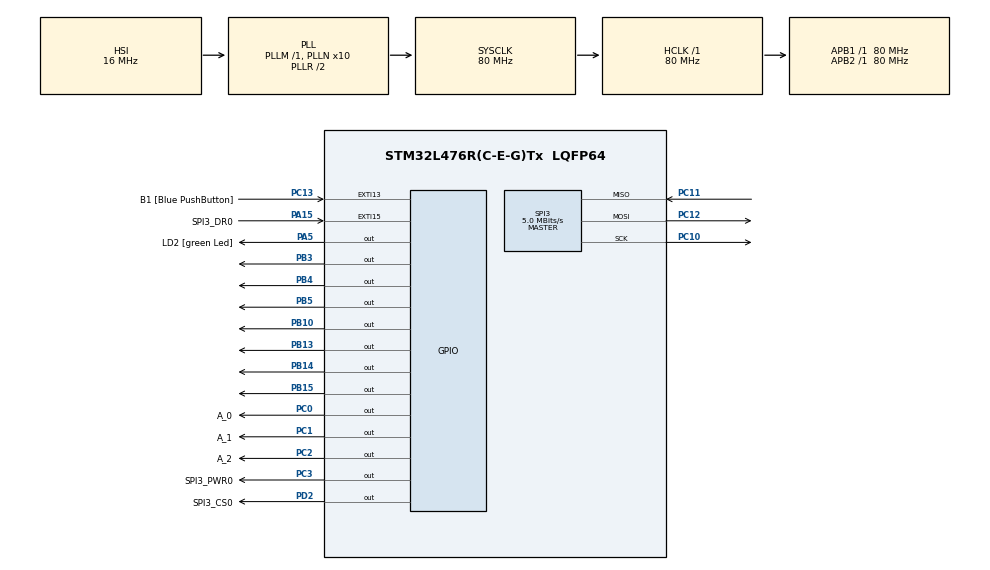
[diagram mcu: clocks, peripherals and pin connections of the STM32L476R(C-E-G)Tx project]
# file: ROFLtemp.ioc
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Mcu.Family=STM32L4
Mcu.Name=STM32L476R(C-E-G)Tx
Mcu.Package=LQFP64
NVIC.EXTI15_10_IRQn=true\:0\:0\:false\:false\:true
NVIC.PriorityGroup=NVIC_PRIORITYGROUP_4
NVIC.SPI3_IRQn=true\:0\:0\:false\:false\:true
NVIC.TIM6_DAC_IRQn=true\:0\:0\:false\:false\:true
PA13.GPIO_Label=TMS
PA13.Signal=SYS_JTMS-SWDIO
PA14.GPIO_Label=TCK
PA14.Signal=SYS_JTCK-SWCLK
PA15.GPIO_Label=SPI3_DR0
PA15.Signal=GPXTI15
PA2.GPIO_Label=USART_TX
PA2.GPIO_Mode=GPIO_MODE_AF_PP
PA2.GPIO_PuPd=GPIO_NOPULL
PA2.GPIO_Speed=GPIO_SPEED_FREQ_VERY_HIGH
PA2.Signal=USART2_TX
PA3.GPIO_Label=USART_RX
PA3.GPIO_Mode=GPIO_MODE_AF_PP
PA3.GPIO_PuPd=GPIO_NOPULL
PA3.GPIO_Speed=GPIO_SPEED_FREQ_VERY_HIGH
PA3.Signal=USART2_RX
PA5.GPIO_Label=LD2 [green Led]
PA5.GPIO_ModeDefaultOutputPP=GPIO_MODE_OUTPUT_PP
PA5.GPIO_PuPd=GPIO_NOPULL
PA5.GPIO_Speed=GPIO_SPEED_FREQ_LOW
PA5.Signal=GPIO_Output
PB10.GPIO_ModeDefaultOutputPP=GPIO_MODE_OUTPUT_PP
PB10.GPIO_Speed=GPIO_SPEED_FREQ_MEDIUM
PB10.PinState=GPIO_PIN_SET
PB10.Signal=GPIO_Output
PB13.GPIO_ModeDefaultOutputPP=GPIO_MODE_OUTPUT_PP
PB13.GPIO_Speed=GPIO_SPEED_FREQ_MEDIUM
PB13.PinState=GPIO_PIN_SET
PB13.Signal=GPIO_Output
PB14.GPIO_ModeDefaultOutputPP=GPIO_MODE_OUTPUT_PP
PB14.GPIO_Speed=GPIO_SPEED_FREQ_MEDIUM
PB14.PinState=GPIO_PIN_SET
PB14.Signal=GPIO_Output
PB15.GPIO_ModeDefaultOutputPP=GPIO_MODE_OUTPUT_PP
PB15.GPIO_Speed=GPIO_SPEED_FREQ_MEDIUM
PB15.PinState=GPIO_PIN_SET
PB15.Signal=GPIO_Output
PB3.GPIO_ModeDefaultOutputPP=GPIO_MODE_OUTPUT_PP
PB3.GPIO_Speed=GPIO_SPEED_FREQ_MEDIUM
PB3.PinState=GPIO_PIN_SET
PB3.Signal=GPIO_Output
PB4.GPIO_ModeDefaultOutputPP=GPIO_MODE_OUTPUT_PP
PB4.GPIO_Speed=GPIO_SPEED_FREQ_MEDIUM
PB4.PinState=GPIO_PIN_SET
PB4.Signal=GPIO_Output
PB5.GPIO_ModeDefaultOutputPP=GPIO_MODE_OUTPUT_PP
PB5.GPIO_Speed=GPIO_SPEED_FREQ_MEDIUM
PB5.PinState=GPIO_PIN_SET
PB5.Signal=GPIO_Output
PC0.GPIO_Label=A_0
PC0.GPIO_Speed=GPIO_SPEED_FREQ_MEDIUM
PC0.Signal=GPIO_Output
PC1.GPIO_Label=A_1
PC1.GPIO_Speed=GPIO_SPEED_FREQ_MEDIUM
PC1.Signal=GPIO_Output
PC10.Mode=Full_Duplex_Master
PC10.Signal=SPI3_SCK
PC11.Mode=Full_Duplex_Master
PC11.Signal=SPI3_MISO
PC12.Mode=Full_Duplex_Master
PC12.Signal=SPI3_MOSI
PC13.GPIO_Label=B1 [Blue PushButton]
PC13.GPIO_ModeDefaultEXTI=GPIO_MODE_IT_FALLING
PC13.GPIO_PuPd=GPIO_NOPULL
PC13.Signal=GPXTI13
PC14/OSC32_IN.Signal=RCC_OSC32_IN
PC15/OSC32_OUT.Signal=RCC_OSC32_OUT
PC2.GPIO_Label=A_2
PC2.GPIO_Speed=GPIO_SPEED_FREQ_MEDIUM
PC2.Signal=GPIO_Output
PC3.GPIO_Label=SPI3_PWR0
PC3.Signal=GPIO_Output
PD2.GPIO_Label=SPI3_CS0
PD2.Signal=GPIO_Output
PH0/OSC_IN.Signal=RCC_OSC_IN
PH1/OSC_OUT.Signal=RCC_OSC_OUT
ProjectManager.HeapSize=0x200
ProjectManager.StackSize=0x400
ProjectManager.TargetToolchain=SW4STM32
RCC.ADCFreq_Value=64000000
RCC.AHBFreq_Value=80000000
RCC.APB1Freq_Value=80000000
RCC.APB1TimFreq_Value=80000000
RCC.APB2Freq_Value=80000000
RCC.APB2TimFreq_Value=80000000
RCC.CortexFreq_Value=80000000
RCC.HCLKFreq_Value=80000000
RCC.HSE_VALUE=8000000
RCC.HSI_VALUE=16000000
RCC.LSE_VALUE=32768
RCC.MSI_VALUE=4000000
RCC.PLLN=10
RCC.PLLSourceVirtual=RCC_PLLSOURCE_HSI
RCC.PREFETCH_ENABLE=1
RCC.SYSCLKFreq_VALUE=80000000
RCC.SYSCLKSource=RCC_SYSCLKSOURCE_PLLCLK
RCC.USBFreq_Value=64000000
RCC.VCOOutputFreq_Value=160000000
SPI3.BaudRatePrescaler=SPI_BAUDRATEPRESCALER_16
SPI3.CLKPhase=SPI_PHASE_2EDGE
SPI3.CLKPolarity=SPI_POLARITY_HIGH
SPI3.CalculateBaudRate=5.0 MBits/s
SPI3.DataSize=SPI_DATASIZE_8BIT
SPI3.Direction=SPI_DIRECTION_2LINES
SPI3.Mode=SPI_MODE_MASTER
SPI3.VirtualType=VM_MASTER
TIM6.Period=100
TIM6.Prescaler=8000
VP_TIM6_VS_ClockSourceINT.Mode=Enable_Timer
board=NUCLEO-L476RG

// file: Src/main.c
/**
  ******************************************************************************
  * File Name          : main.c
  * Description        : Main program body
  ******************************************************************************
  *
  * COPYRIGHT(c) 2017 STMicroelectronics
  *
  * Redistribution and use in source and binary forms, with or without modification,
  * are permitted provided that the following conditions are met:
  *   1. Redistributions of source code must retain the above copyright notice,
  *      this list of conditions and the following disclaimer.
  *   2. Redistributions in binary form must reproduce the above copyright notice,
  *      this list of conditions and the following disclaimer in the documentation
  *      and/or other materials provided with the distribution.
  *   3. Neither the name of STMicroelectronics nor the names of its contributors
  *      may be used to endorse or promote products derived from this software
  *      without specific prior written permission.
  *
  * THIS SOFTWARE IS PROVIDED BY THE COPYRIGHT HOLDERS AND CONTRIBUTORS "AS IS"
  * AND ANY EXPRESS OR IMPLIED WARRANTIES, INCLUDING, BUT NOT LIMITED TO, THE
  * IMPLIED WARRANTIES OF MERCHANTABILITY AND FITNESS FOR A PARTICULAR PURPOSE ARE
  * DISCLAIMED. IN NO EVENT SHALL THE COPYRIGHT HOLDER OR CONTRIBUTORS BE LIABLE
  * FOR ANY DIRECT, INDIRECT, INCIDENTAL, SPECIAL, EXEMPLARY, OR CONSEQUENTIAL
  * DAMAGES (INCLUDING, BUT NOT LIMITED TO, PROCUREMENT OF SUBSTITUTE GOODS OR
  * SERVICES; LOSS OF USE, DATA, OR PROFITS; OR BUSINESS INTERRUPTION) HOWEVER
  * CAUSED AND ON ANY THEORY OF LIABILITY, WHETHER IN CONTRACT, STRICT LIABILITY,
  * OR TORT (INCLUDING NEGLIGENCE OR OTHERWISE) ARISING IN ANY WAY OUT OF THE USE
  * OF THIS SOFTWARE, EVEN IF ADVISED OF THE POSSIBILITY OF SUCH DAMAGE.
  *
  ******************************************************************************
  */
#include "main.h"
#include "stm32l4xx_hal.h"
#include "spi.h"
#include "tim.h"
#include "gpio.h"

/* USER CODE BEGIN Includes */
#include "sevseg.h"
#include "MAX31865.h"
/* USER CODE END Includes */

/* USER CODE BEGIN PV */
/* Private variables ---------------------------------------------------------*/

/* USER CODE END PV */

void SystemClock_Config(void);
void Error_Handler(void);

/* USER CODE BEGIN PFP */
/* Private function prototypes -----------------------------------------------*/

/* USER CODE END PFP */

int main(void)
{

  /* MCU Configuration----------------------------------------------------------*/

  /* Reset of all peripherals, Initializes the Flash interface and the Systick. */
  HAL_Init();

  /* Configure the system clock */
  SystemClock_Config();

  /* Initialize all configured peripherals */
  MX_GPIO_Init();
  MX_TIM6_Init();
  MX_SPI3_Init();

  /* USER CODE BEGIN 2 */
  HAL_TIM_Base_Start_IT(&htim6);

  // Power-off RTD-Frontend
  HAL_GPIO_WritePin( SPI3_PWR0_GPIO_Port, SPI3_PWR0_Pin, GPIO_PIN_RESET );

  HAL_Delay(100);

  // Send a dummy byte on SPI3 to make sure the idle clock is correct
  initSPIIdleClock();

  // Power-on RTD-Frontend
  HAL_GPIO_WritePin( SPI3_PWR0_GPIO_Port, SPI3_PWR0_Pin, GPIO_PIN_SET );

  HAL_Delay(100);

  initMAX31865();
  /* USER CODE END 2 */

  /* Infinite loop */
  /* USER CODE BEGIN WHILE */
  HAL_GPIO_WritePin(GPIOC, GPIO_PIN_0, GPIO_PIN_SET);

  while (1)
  {
    handleMAX31865Devices();
    handleSevSeg();
    checkMAX31865WDG();
  /* USER CODE END WHILE */

  }

}

/** System Clock Configuration
*/
void SystemClock_Config(void)
{

  RCC_OscInitTypeDef RCC_OscInitStruct;
  RCC_ClkInitTypeDef RCC_ClkInitStruct;

    /**Initializes the CPU, AHB and APB busses clocks
    */
  RCC_OscInitStruct.OscillatorType = RCC_OSCILLATORTYPE_HSI;
  RCC_OscInitStruct.HSIState = RCC_HSI_ON;
  RCC_OscInitStruct.HSICalibrationValue = 16;
  RCC_OscInitStruct.PLL.PLLState = RCC_PLL_ON;
  RCC_OscInitStruct.PLL.PLLSource = RCC_PLLSOURCE_HSI;
  RCC_OscInitStruct.PLL.PLLM = 1;
  RCC_OscInitStruct.PLL.PLLN = 10;
  RCC_OscInitStruct.PLL.PLLP = RCC_PLLP_DIV7;
  RCC_OscInitStruct.PLL.PLLQ = RCC_PLLQ_DIV2;
  RCC_OscInitStruct.PLL.PLLR = RCC_PLLR_DIV2;
  if (HAL_RCC_OscConfig(&RCC_OscInitStruct) != HAL_OK)
  {
    Error_Handler();
  }

    /**Initializes the CPU, AHB and APB busses clocks
    */
  RCC_ClkInitStruct.ClockType = RCC_CLOCKTYPE_HCLK|RCC_CLOCKTYPE_SYSCLK
                              |RCC_CLOCKTYPE_PCLK1|RCC_CLOCKTYPE_PCLK2;
  RCC_ClkInitStruct.SYSCLKSource = RCC_SYSCLKSOURCE_PLLCLK;
  RCC_ClkInitStruct.AHBCLKDivider = RCC_SYSCLK_DIV1;
  RCC_ClkInitStruct.APB1CLKDivider = RCC_HCLK_DIV1;
  RCC_ClkInitStruct.APB2CLKDivider = RCC_HCLK_DIV1;

  if (HAL_RCC_ClockConfig(&RCC_ClkInitStruct, FLASH_LATENCY_4) != HAL_OK)
  {
    Error_Handler();
  }

    /**Configure the main internal regulator output voltage
    */
  if (HAL_PWREx_ControlVoltageScaling(PWR_REGULATOR_VOLTAGE_SCALE1) != HAL_OK)
  {
    Error_Handler();
  }

    /**Configure the Systick interrupt time
    */
  HAL_SYSTICK_Config(HAL_RCC_GetHCLKFreq()/1000);

    /**Configure the Systick
    */
  HAL_SYSTICK_CLKSourceConfig(SYSTICK_CLKSOURCE_HCLK);

  /* SysTick_IRQn interrupt configuration */
  HAL_NVIC_SetPriority(SysTick_IRQn, 0, 0);
}

void Error_Handler(void)
{
  while(1)
  {
  }
}

/************************ (C) COPYRIGHT STMicroelectronics *****END OF FILE****/
